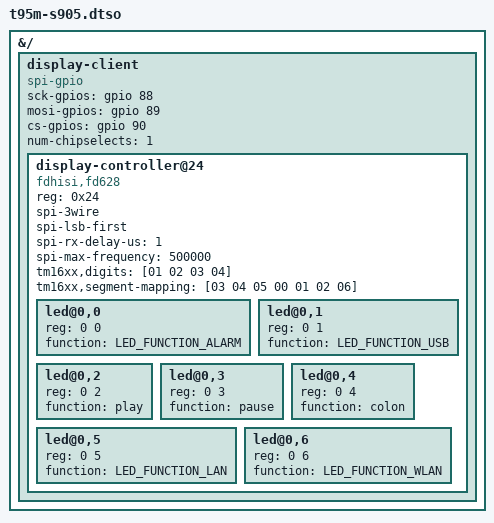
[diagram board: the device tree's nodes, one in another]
/dts-v1/;
/plugin/;

#include <dt-bindings/gpio/gpio.h>
#include <dt-bindings/leds/common.h>

&{/} {

	display-client {
		#address-cells = <1>;
		#size-cells = <0>;
		compatible = "spi-gpio";
		sck-gpios = <&gpio 88 0>;
		mosi-gpios = <&gpio 89 0>;
		cs-gpios = <&gpio 90 0>;
		num-chipselects = <1>;

		display-controller@24 {
			compatible = "fdhisi,fd628";
			reg = <0x24>;
			spi-3wire;
			spi-lsb-first;
			spi-rx-delay-us = <1>;
			spi-max-frequency = <500000>;

			tm16xx,digits = [01 02 03 04];
                        tm16xx,segment-mapping = [03 04 05 00 01 02 06];

			#address-cells = <2>;
			#size-cells = <0>;
			
			led@0,0 {
				reg = <0 0>;
				function = LED_FUNCTION_ALARM;
			};
			
			led@0,1 {
				reg = <0 1>;
				function = LED_FUNCTION_USB;
			};
			
			led@0,2 {
				reg = <0 2>;
				function = "play";
			};
			
			led@0,3 {
				reg = <0 3>;
				function = "pause";
			};
			
			led@0,4 {
				reg = <0 4>;
				function = "colon";
			};
			
			led@0,5 {
				reg = <0 5>;
				function = LED_FUNCTION_LAN;
			};
			
			led@0,6 {
				reg = <0 6>;
				function = LED_FUNCTION_WLAN;
			};

		};
	};
};

